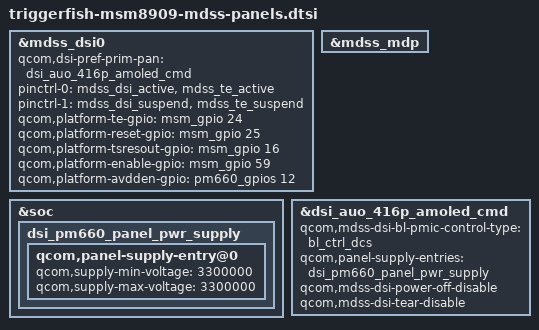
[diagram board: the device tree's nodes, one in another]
/* Copyright (c) 2014-2018, The Linux Foundation. All rights reserved.
 *
 * This program is free software; you can redistribute it and/or modify
 * it under the terms of the GNU General Public License version 2 and
 * only version 2 as published by the Free Software Foundation.
 *
 * This program is distributed in the hope that it will be useful,
 * but WITHOUT ANY WARRANTY; without even the implied warranty of
 * MERCHANTABILITY or FITNESS FOR A PARTICULAR PURPOSE.  See the
 * GNU General Public License for more details.
 */

#include "triggerfish-dsi-panel-auo-416p-amoled-cmd.dtsi"

&mdss_dsi0 {
	qcom,dsi-pref-prim-pan = <&dsi_auo_416p_amoled_cmd>;
	pinctrl-names = "mdss_default", "mdss_sleep";
	pinctrl-0 = <&mdss_dsi_active &mdss_te_active>;
	pinctrl-1 = <&mdss_dsi_suspend &mdss_te_suspend>;

	qcom,platform-te-gpio = <&msm_gpio 24 0>;
	qcom,platform-reset-gpio = <&msm_gpio 25 0>;
	qcom,platform-tsresout-gpio = <&msm_gpio 16 0>;
	qcom,platform-enable-gpio = <&msm_gpio 59 0>;
	qcom,platform-avdden-gpio = <&pm660_gpios 12 0>;
	/delete-property/ qcom,platform-bklight-en-gpio;
};
&mdss_mdp {
	/delete-node/ qcom,mdss_dsi_auo_390p_cmd;
};
&soc {
	dsi_pm660_panel_pwr_supply {
		qcom,panel-supply-entry@0 {
			/delete-property/ qcom,supply-min-voltage;
			/delete-property/ qcom,supply-max-voltage;
			qcom,supply-min-voltage = <3300000>;
			qcom,supply-max-voltage = <3300000>;
		};
	};
};
&dsi_auo_416p_amoled_cmd {
	qcom,mdss-dsi-bl-pmic-control-type = "bl_ctrl_dcs";
	qcom,panel-supply-entries = <&dsi_pm660_panel_pwr_supply>;
	qcom,mdss-dsi-power-off-disable;
	qcom,mdss-dsi-tear-disable;
};
